# ESP32C3 register map
File version: 1.0
CPU: RISC-V RV32IMC single-core 1, little endian, no MPU, FPU, 3 interrupt priority bits
Registers are 32-bit, read-write, reset 0x0 unless marked. A register's access mark holds for its fields unless they carry their own. Offsets are from the block's base; [hi:lo] are bit positions; {n}, {i} and the like mark numbered series.

## EXTMEM
Base 0x600C4000
0x00 EXTMEM_ICACHE_CTRL
  [0] EXTMEM_ICACHE_ENABLE
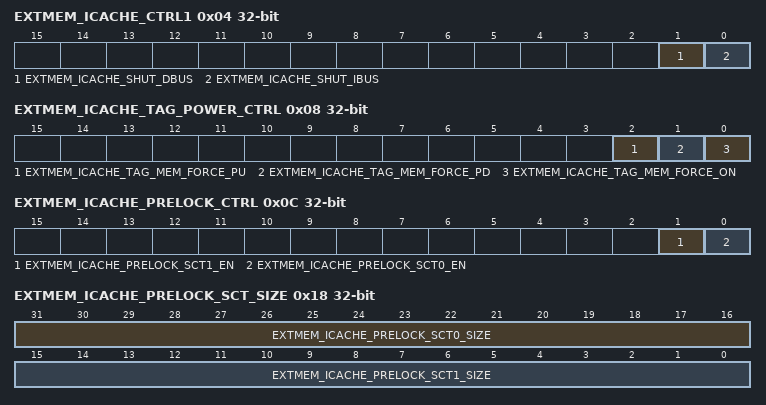
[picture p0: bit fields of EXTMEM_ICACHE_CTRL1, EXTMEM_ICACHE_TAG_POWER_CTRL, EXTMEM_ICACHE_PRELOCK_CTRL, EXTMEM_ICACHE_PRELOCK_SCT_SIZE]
0x04 EXTMEM_ICACHE_CTRL1
  [1] EXTMEM_ICACHE_SHUT_DBUS, [0] EXTMEM_ICACHE_SHUT_IBUS
0x08 EXTMEM_ICACHE_TAG_POWER_CTRL
  [2] EXTMEM_ICACHE_TAG_MEM_FORCE_PU, [1] EXTMEM_ICACHE_TAG_MEM_FORCE_PD, [0] EXTMEM_ICACHE_TAG_MEM_FORCE_ON
0x0C EXTMEM_ICACHE_PRELOCK_CTRL
  [1] EXTMEM_ICACHE_PRELOCK_SCT1_EN, [0] EXTMEM_ICACHE_PRELOCK_SCT0_EN
0x10 EXTMEM_ICACHE_PRELOCK_SCT0_ADDR
0x14 EXTMEM_ICACHE_PRELOCK_SCT1_ADDR
0x18 EXTMEM_ICACHE_PRELOCK_SCT_SIZE
  [31:16] EXTMEM_ICACHE_PRELOCK_SCT0_SIZE, [15:0] EXTMEM_ICACHE_PRELOCK_SCT1_SIZE
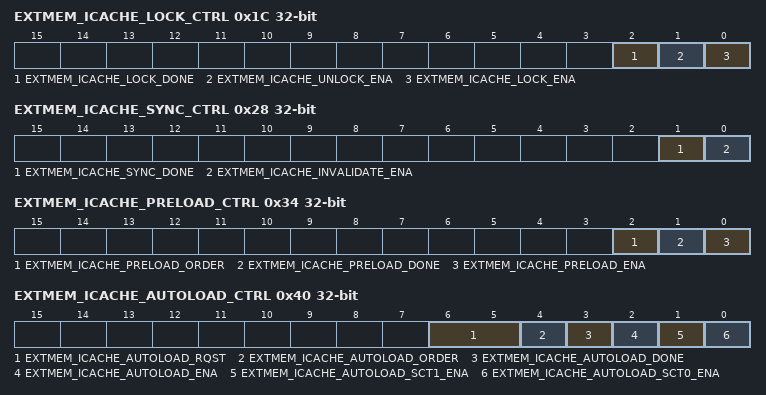
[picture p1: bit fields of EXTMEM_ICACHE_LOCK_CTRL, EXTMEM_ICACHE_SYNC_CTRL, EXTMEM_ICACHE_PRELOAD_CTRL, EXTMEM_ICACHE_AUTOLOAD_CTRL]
0x1C EXTMEM_ICACHE_LOCK_CTRL access per field
  [2] EXTMEM_ICACHE_LOCK_DONE ro, [1] EXTMEM_ICACHE_UNLOCK_ENA rw, [0] EXTMEM_ICACHE_LOCK_ENA rw
0x20 EXTMEM_ICACHE_LOCK_ADDR
0x24 EXTMEM_ICACHE_LOCK_SIZE
  [15:0] EXTMEM_ICACHE_LOCK_SIZE
0x28 EXTMEM_ICACHE_SYNC_CTRL access per field
  [1] EXTMEM_ICACHE_SYNC_DONE ro, [0] EXTMEM_ICACHE_INVALIDATE_ENA rw
0x2C EXTMEM_ICACHE_SYNC_ADDR
0x30 EXTMEM_ICACHE_SYNC_SIZE
  [22:0] EXTMEM_ICACHE_SYNC_SIZE
0x34 EXTMEM_ICACHE_PRELOAD_CTRL access per field
  [2] EXTMEM_ICACHE_PRELOAD_ORDER rw, [1] EXTMEM_ICACHE_PRELOAD_DONE ro, [0] EXTMEM_ICACHE_PRELOAD_ENA rw
0x38 EXTMEM_ICACHE_PRELOAD_ADDR
0x3C EXTMEM_ICACHE_PRELOAD_SIZE
  [15:0] EXTMEM_ICACHE_PRELOAD_SIZE
0x40 EXTMEM_ICACHE_AUTOLOAD_CTRL access per field
  [6:5] EXTMEM_ICACHE_AUTOLOAD_RQST rw, [4] EXTMEM_ICACHE_AUTOLOAD_ORDER rw, [3] EXTMEM_ICACHE_AUTOLOAD_DONE ro, [2] EXTMEM_ICACHE_AUTOLOAD_ENA rw, [1] EXTMEM_ICACHE_AUTOLOAD_SCT1_ENA rw, [0] EXTMEM_ICACHE_AUTOLOAD_SCT0_ENA rw
0x44 EXTMEM_ICACHE_AUTOLOAD_SCT0_ADDR
0x48 EXTMEM_ICACHE_AUTOLOAD_SCT0_SIZE
  [26:0] EXTMEM_ICACHE_AUTOLOAD_SCT0_SIZE
0x4C EXTMEM_ICACHE_AUTOLOAD_SCT1_ADDR
0x50 EXTMEM_ICACHE_AUTOLOAD_SCT1_SIZE
  [26:0] EXTMEM_ICACHE_AUTOLOAD_SCT1_SIZE
0x54 EXTMEM_IBUS_TO_FLASH_START_VADDR
0x58 EXTMEM_IBUS_TO_FLASH_END_VADDR
0x5C EXTMEM_DBUS_TO_FLASH_START_VADDR
0x60 EXTMEM_DBUS_TO_FLASH_END_VADDR
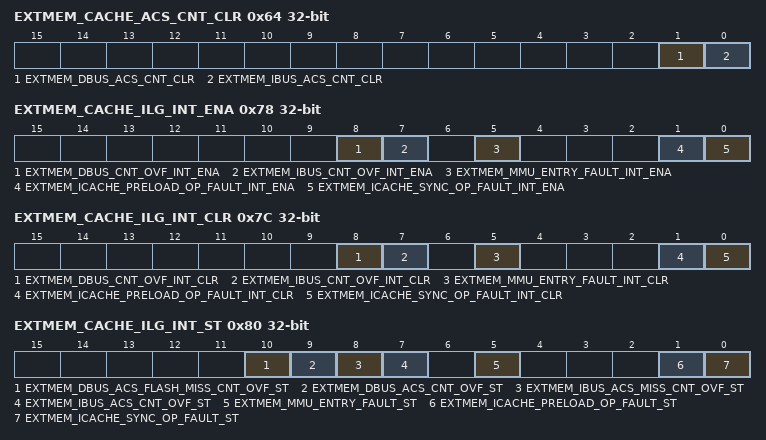
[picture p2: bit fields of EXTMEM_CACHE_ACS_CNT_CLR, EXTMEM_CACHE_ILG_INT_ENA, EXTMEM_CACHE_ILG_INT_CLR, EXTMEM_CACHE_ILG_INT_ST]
0x64 EXTMEM_CACHE_ACS_CNT_CLR wo
  [1] EXTMEM_DBUS_ACS_CNT_CLR, [0] EXTMEM_IBUS_ACS_CNT_CLR
0x68 EXTMEM_IBUS_ACS_MISS_CNT ro
0x6C EXTMEM_IBUS_ACS_CNT ro
0x70 EXTMEM_DBUS_ACS_FLASH_MISS_CNT ro
0x74 EXTMEM_DBUS_ACS_CNT ro
0x78 EXTMEM_CACHE_ILG_INT_ENA
  [8] EXTMEM_DBUS_CNT_OVF_INT_ENA, [7] EXTMEM_IBUS_CNT_OVF_INT_ENA, [5] EXTMEM_MMU_ENTRY_FAULT_INT_ENA, [1] EXTMEM_ICACHE_PRELOAD_OP_FAULT_INT_ENA, [0] EXTMEM_ICACHE_SYNC_OP_FAULT_INT_ENA
0x7C EXTMEM_CACHE_ILG_INT_CLR wo
  [8] EXTMEM_DBUS_CNT_OVF_INT_CLR, [7] EXTMEM_IBUS_CNT_OVF_INT_CLR, [5] EXTMEM_MMU_ENTRY_FAULT_INT_CLR, [1] EXTMEM_ICACHE_PRELOAD_OP_FAULT_INT_CLR, [0] EXTMEM_ICACHE_SYNC_OP_FAULT_INT_CLR
0x80 EXTMEM_CACHE_ILG_INT_ST ro
  [10] EXTMEM_DBUS_ACS_FLASH_MISS_CNT_OVF_ST, [9] EXTMEM_DBUS_ACS_CNT_OVF_ST, [8] EXTMEM_IBUS_ACS_MISS_CNT_OVF_ST, [7] EXTMEM_IBUS_ACS_CNT_OVF_ST, [5] EXTMEM_MMU_ENTRY_FAULT_ST, [1] EXTMEM_ICACHE_PRELOAD_OP_FAULT_ST, [0] EXTMEM_ICACHE_SYNC_OP_FAULT_ST
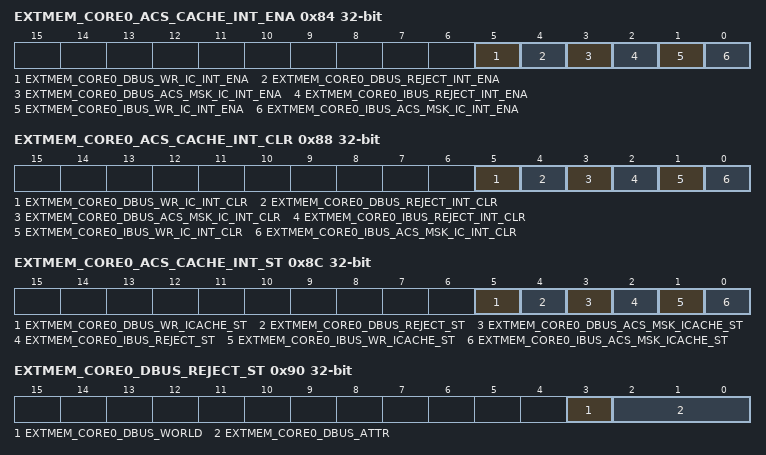
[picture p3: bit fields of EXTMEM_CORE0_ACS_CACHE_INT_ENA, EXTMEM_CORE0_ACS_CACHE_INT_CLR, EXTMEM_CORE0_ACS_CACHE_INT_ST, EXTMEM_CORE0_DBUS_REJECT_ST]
0x84 EXTMEM_CORE0_ACS_CACHE_INT_ENA
  [5] EXTMEM_CORE0_DBUS_WR_IC_INT_ENA, [4] EXTMEM_CORE0_DBUS_REJECT_INT_ENA, [3] EXTMEM_CORE0_DBUS_ACS_MSK_IC_INT_ENA, [2] EXTMEM_CORE0_IBUS_REJECT_INT_ENA, [1] EXTMEM_CORE0_IBUS_WR_IC_INT_ENA, [0] EXTMEM_CORE0_IBUS_ACS_MSK_IC_INT_ENA
0x88 EXTMEM_CORE0_ACS_CACHE_INT_CLR wo
  [5] EXTMEM_CORE0_DBUS_WR_IC_INT_CLR, [4] EXTMEM_CORE0_DBUS_REJECT_INT_CLR, [3] EXTMEM_CORE0_DBUS_ACS_MSK_IC_INT_CLR, [2] EXTMEM_CORE0_IBUS_REJECT_INT_CLR, [1] EXTMEM_CORE0_IBUS_WR_IC_INT_CLR, [0] EXTMEM_CORE0_IBUS_ACS_MSK_IC_INT_CLR
0x8C EXTMEM_CORE0_ACS_CACHE_INT_ST ro
  [5] EXTMEM_CORE0_DBUS_WR_ICACHE_ST, [4] EXTMEM_CORE0_DBUS_REJECT_ST, [3] EXTMEM_CORE0_DBUS_ACS_MSK_ICACHE_ST, [2] EXTMEM_CORE0_IBUS_REJECT_ST, [1] EXTMEM_CORE0_IBUS_WR_ICACHE_ST, [0] EXTMEM_CORE0_IBUS_ACS_MSK_ICACHE_ST
0x90 EXTMEM_CORE0_DBUS_REJECT_ST ro
  [3] EXTMEM_CORE0_DBUS_WORLD, [2:0] EXTMEM_CORE0_DBUS_ATTR
0x94 EXTMEM_CORE0_DBUS_REJECT_VADDR ro
  [31:0] EXTMEM_CORE0_DBUS_VADDR
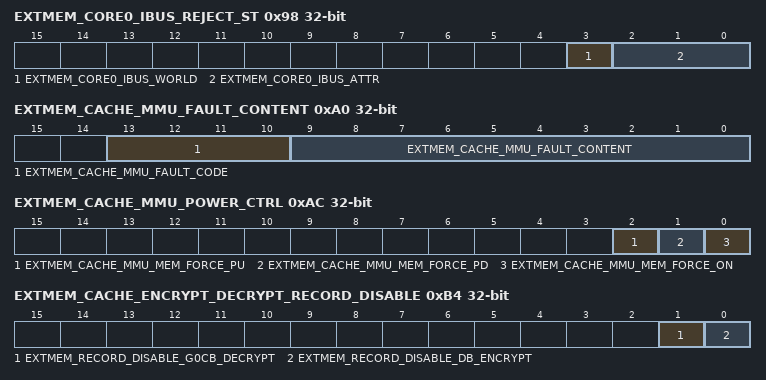
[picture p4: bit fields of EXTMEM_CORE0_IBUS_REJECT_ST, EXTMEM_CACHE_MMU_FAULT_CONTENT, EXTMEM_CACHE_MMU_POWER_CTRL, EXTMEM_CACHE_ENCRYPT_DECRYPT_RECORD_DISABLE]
0x98 EXTMEM_CORE0_IBUS_REJECT_ST ro
  [3] EXTMEM_CORE0_IBUS_WORLD, [2:0] EXTMEM_CORE0_IBUS_ATTR
0x9C EXTMEM_CORE0_IBUS_REJECT_VADDR ro
  [31:0] EXTMEM_CORE0_IBUS_VADDR
0xA0 EXTMEM_CACHE_MMU_FAULT_CONTENT ro
  [13:10] EXTMEM_CACHE_MMU_FAULT_CODE, [9:0] EXTMEM_CACHE_MMU_FAULT_CONTENT
0xA4 EXTMEM_CACHE_MMU_FAULT_VADDR ro
0xA8 EXTMEM_CACHE_WRAP_AROUND_CTRL
  [0] EXTMEM_CACHE_FLASH_WRAP_AROUND
0xAC EXTMEM_CACHE_MMU_POWER_CTRL
  [2] EXTMEM_CACHE_MMU_MEM_FORCE_PU, [1] EXTMEM_CACHE_MMU_MEM_FORCE_PD, [0] EXTMEM_CACHE_MMU_MEM_FORCE_ON
0xB0 EXTMEM_CACHE_STATE ro
  [11:0] EXTMEM_ICACHE_STATE
0xB4 EXTMEM_CACHE_ENCRYPT_DECRYPT_RECORD_DISABLE
  [1] EXTMEM_RECORD_DISABLE_G0CB_DECRYPT, [0] EXTMEM_RECORD_DISABLE_DB_ENCRYPT
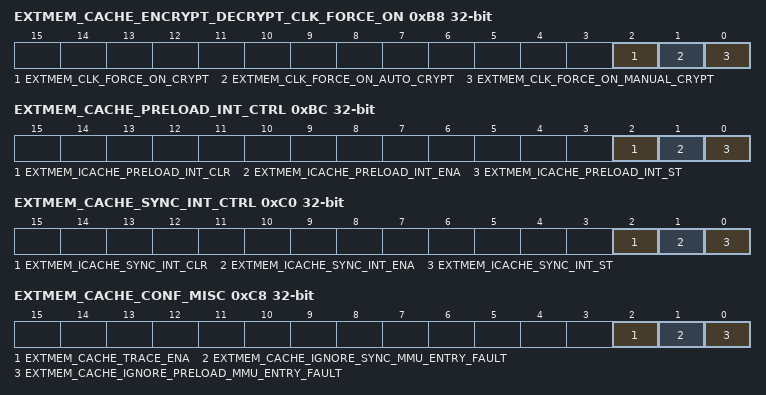
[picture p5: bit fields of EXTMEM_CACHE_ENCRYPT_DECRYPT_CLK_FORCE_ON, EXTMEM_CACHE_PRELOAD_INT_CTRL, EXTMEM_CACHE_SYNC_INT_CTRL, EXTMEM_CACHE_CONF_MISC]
0xB8 EXTMEM_CACHE_ENCRYPT_DECRYPT_CLK_FORCE_ON
  [2] EXTMEM_CLK_FORCE_ON_CRYPT, [1] EXTMEM_CLK_FORCE_ON_AUTO_CRYPT, [0] EXTMEM_CLK_FORCE_ON_MANUAL_CRYPT
0xBC EXTMEM_CACHE_PRELOAD_INT_CTRL access per field
  [2] EXTMEM_ICACHE_PRELOAD_INT_CLR wo, [1] EXTMEM_ICACHE_PRELOAD_INT_ENA rw, [0] EXTMEM_ICACHE_PRELOAD_INT_ST ro
0xC0 EXTMEM_CACHE_SYNC_INT_CTRL access per field
  [2] EXTMEM_ICACHE_SYNC_INT_CLR wo, [1] EXTMEM_ICACHE_SYNC_INT_ENA rw, [0] EXTMEM_ICACHE_SYNC_INT_ST ro
0xC4 EXTMEM_CACHE_MMU_OWNER
  [3:0] EXTMEM_CACHE_MMU_OWNER
0xC8 EXTMEM_CACHE_CONF_MISC
  [2] EXTMEM_CACHE_TRACE_ENA, [1] EXTMEM_CACHE_IGNORE_SYNC_MMU_ENTRY_FAULT, [0] EXTMEM_CACHE_IGNORE_PRELOAD_MMU_ENTRY_FAULT
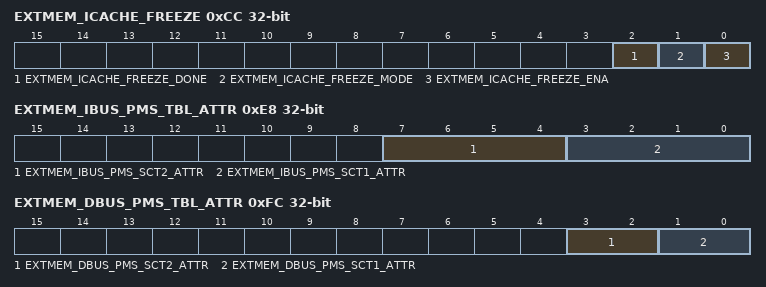
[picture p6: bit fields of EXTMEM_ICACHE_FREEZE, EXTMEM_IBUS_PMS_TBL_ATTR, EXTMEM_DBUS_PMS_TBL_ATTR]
0xCC EXTMEM_ICACHE_FREEZE access per field
  [2] EXTMEM_ICACHE_FREEZE_DONE ro, [1] EXTMEM_ICACHE_FREEZE_MODE rw, [0] EXTMEM_ICACHE_FREEZE_ENA rw
0xD0 EXTMEM_ICACHE_ATOMIC_OPERATE_ENA
  [0] EXTMEM_ICACHE_ATOMIC_OPERATE_ENA
0xD4 EXTMEM_CACHE_REQUEST
  [0] EXTMEM_CACHE_REQUEST_BYPASS
0xD8 EXTMEM_IBUS_PMS_TBL_LOCK
  [0] EXTMEM_IBUS_PMS_LOCK
{0xDC+4i} EXTMEM_IBUS_PMS_TBL_BOUNDARY{i} (i=0..2)
  [11:0] EXTMEM_IBUS_PMS_BOUNDARY{i}
0xE8 EXTMEM_IBUS_PMS_TBL_ATTR
  [7:4] EXTMEM_IBUS_PMS_SCT2_ATTR, [3:0] EXTMEM_IBUS_PMS_SCT1_ATTR
0xEC EXTMEM_DBUS_PMS_TBL_LOCK
  [0] EXTMEM_DBUS_PMS_LOCK
{0xF0+4i} EXTMEM_DBUS_PMS_TBL_BOUNDARY{i} (i=0..2)
  [11:0] EXTMEM_DBUS_PMS_BOUNDARY{i}
0xFC EXTMEM_DBUS_PMS_TBL_ATTR
  [3:2] EXTMEM_DBUS_PMS_SCT2_ATTR, [1:0] EXTMEM_DBUS_PMS_SCT1_ATTR
0x100 EXTMEM_CLOCK_GATE
  [0] EXTMEM_CLK_EN
0x3FC EXTMEM_DATE
  [27:0] EXTMEM_DATE
